# Timer32_356.0 register map
Vendor: Texas Instruments
Peripheral module from a debugger description file (folder MSP432).
Registers are 32-bit, access not given, no defined reset value unless marked. A register's access mark holds for its fields unless they carry their own. Offsets are as the file gives them; lines under a group give offsets from that group; [hi:lo] are bit positions; {n}, {i} and the like mark numbered series; 'fields as' and 'values as' point back to an identical list; <NAME> marks a mode.

## Timer32
0x00 T32LOAD1 — Timer 1 Load Register
0x04 T32VALUE1 — Timer 1 Current Value Register
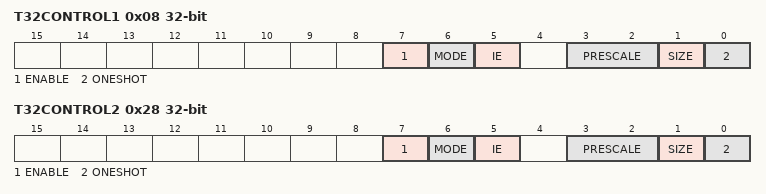
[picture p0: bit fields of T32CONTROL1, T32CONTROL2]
0x08 T32CONTROL1 rw — Timer 1 Timer Control Register
  [7] ENABLE — Enable bit
    0=DISABLE (Timer disabled); 1=ENABLE (Timer enabled)
  [6] MODE — Mode bit
    0=FREE (Timer is in free-running mode); 1=PERIODIC (Timer is in periodic mode)
  [5] IE — Interrupt enable bit
    0=DISABLE (Timer interrupt disabled); 1=ENABLE (Timer interrupt enabled)
  [3:2] PRESCALE — Prescale bits
    0=0 stages of prescale, clock is divided by 1; 1=4 stages of prescale, clock is divided by 16; 2=8 stages of prescale, clock is divided by 256
  [1] SIZE — Selects 16 or 32 bit counter operation
    0=16BIT (16-bit counter); 1=32BIT (32-bit counter)
  [0] ONESHOT — Selects one-shot or wrapping counter mode
    0=WRAPPING (wrapping mode); 1=ONESHOT (one-shot mode)
0x0C T32INTCLR1 — Timer 1 Interrupt Clear Register
0x10 T32RIS1 ro — Timer 1 Raw Interrupt Status Register
  [0] RAW_IFG — Raw interrupt status
0x14 T32MIS1 ro — Timer 1 Interrupt Status Register
  [0] IFG — Enabled interrupt status
0x18 T32BGLOAD1 — Timer 1 Background Load Register
0x20 T32LOAD2 — Timer 2 Load Register
0x24 T32VALUE2 — Timer 2 Current Value Register
0x28 T32CONTROL2 rw — Timer 2 Timer Control Register
  fields as T32CONTROL1
0x2C T32INTCLR2 — Timer 2 Interrupt Clear Register
0x30 T32RIS2 ro — Timer 2 Raw Interrupt Status Register
  [0] RAW_IFG — Raw interrupt status
0x34 T32MIS2 ro — Timer 2 Interrupt Status Register
  [0] IFG — Enabled interrupt status
0x38 T32BGLOAD2 — Timer 2 Background Load Register
